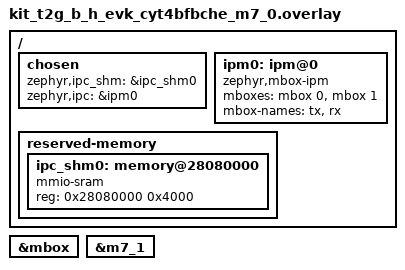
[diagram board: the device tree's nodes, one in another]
/*
 * Copyright (c) 2026 Infineon Technologies AG
 * SPDX-License-Identifier: Apache-2.0
 *
 * OpenAMP IPC overlay for kit_t2g_b_h_evk (CYT4BFBCHE) - Host (CM7_0)
 */

/ {
	chosen {
		zephyr,ipc_shm = &ipc_shm0;
		zephyr,ipc = &ipm0;
	};

	ipm0: ipm@0 {
		compatible = "zephyr,mbox-ipm";
		mboxes = <&mbox 0>, <&mbox 1>;
		mbox-names = "tx", "rx";
		status = "okay";
	};

	reserved-memory {
		#address-cells = <1>;
		#size-cells = <1>;

		/*
		 * Shared memory region for IPC between CM7_0 and M0+/M7_1
		 * Located in sram2 to avoid conflicts
		 * Address: 0x28080000 (start of sram2)
		 * Size: 16KB (0x4000)
		 */
		ipc_shm0: memory@28080000 {
			compatible = "mmio-sram";
			reg = <0x28080000 0x4000>;
		};
	};
};

&mbox {
	status = "okay";
};

&m7_1 {
	status = "okay";
};
